# ESP32-P4-LP register map
Vendor: ESPRESSIF SYSTEMS (SHANGHAI) CO., LTD.; Series: ESP32 P-Series; File version: 3
CPU: RV32IMAC r0p0, little endian, no MPU, no FPU, 0 interrupt priority bits
Address unit: 32 bits
Registers are 32-bit, read-write, reset 0x0 unless marked. A register's access mark holds for its fields unless they carry their own. Offsets are from the block's base; [hi:lo] are bit positions; {n}, {i} and the like mark numbered series; 'fields as' and 'values as' point back to an identical list.

## LP_I2C_ANA_MST — LP_I2C_ANA_MST Peripheral
Base 0x50124000
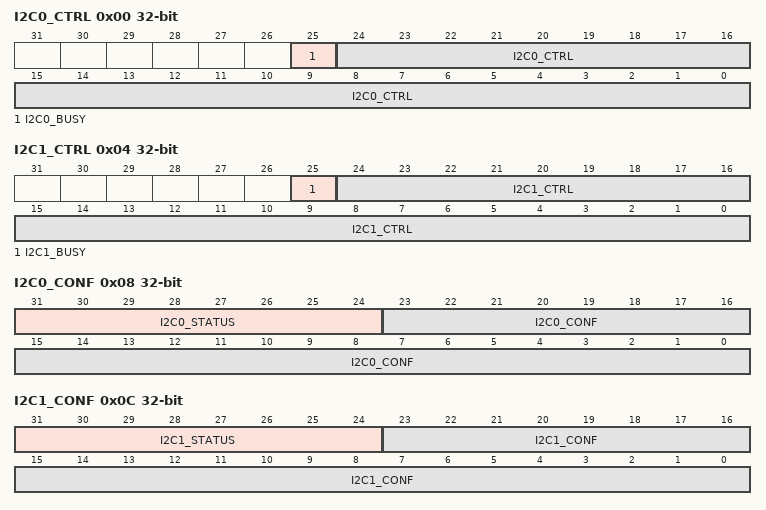
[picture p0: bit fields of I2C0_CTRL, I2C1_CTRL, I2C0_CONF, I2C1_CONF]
0x00 I2C0_CTRL access per field — need des
  [25] I2C0_BUSY ro — need des
  [24:0] I2C0_CTRL rw — need des
0x04 I2C1_CTRL access per field — need des
  [25] I2C1_BUSY ro — need des
  [24:0] I2C1_CTRL rw — need des
0x08 I2C0_CONF access per field — need des
  [31:24] I2C0_STATUS ro — need des
  [23:0] I2C0_CONF rw — need des
0x0C I2C1_CONF access per field — need des
  [31:24] I2C1_STATUS ro — need des
  [23:0] I2C1_CONF rw — need des
0x10 I2C_BURST_CONF — need des
  [31:0] I2C_MST_BURST_CTRL
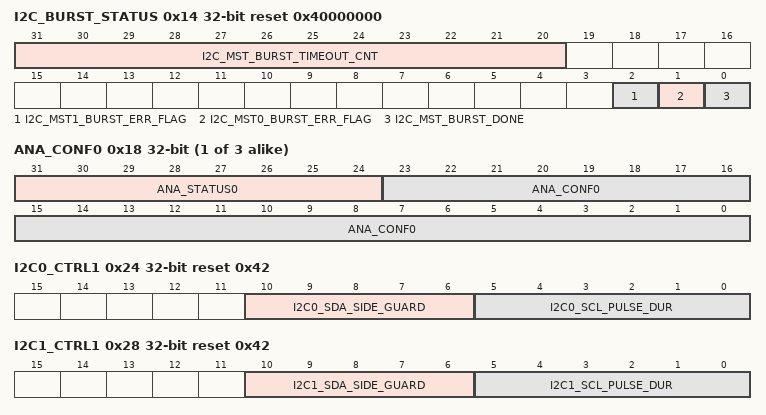
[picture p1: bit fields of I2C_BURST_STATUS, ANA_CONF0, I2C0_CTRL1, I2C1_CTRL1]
0x14 I2C_BURST_STATUS access per field reset 0x40000000 — need des
  [31:20] I2C_MST_BURST_TIMEOUT_CNT rw — need des
  [2] I2C_MST1_BURST_ERR_FLAG ro — need des
  [1] I2C_MST0_BURST_ERR_FLAG ro — need des
  [0] I2C_MST_BURST_DONE ro — need des
{0x18+4i} ANA_CONF{i} access per field (i=0..2) — need des
  [31:24] ANA_STATUS{i} ro — need des
  [23:0] ANA_CONF{i} rw — need des
0x24 I2C0_CTRL1 reset 0x42 — need des
  [10:6] I2C0_SDA_SIDE_GUARD — need des
  [5:0] I2C0_SCL_PULSE_DUR — need des
0x28 I2C1_CTRL1 reset 0x42 — need des
  [10:6] I2C1_SDA_SIDE_GUARD — need des
  [5:0] I2C1_SCL_PULSE_DUR — need des
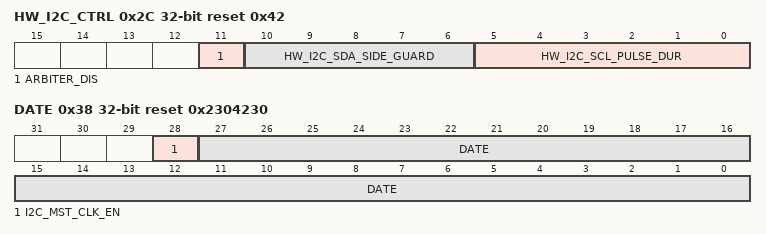
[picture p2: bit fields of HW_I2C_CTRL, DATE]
0x2C HW_I2C_CTRL reset 0x42 — need des
  [11] ARBITER_DIS — need des
  [10:6] HW_I2C_SDA_SIDE_GUARD — need des
  [5:0] HW_I2C_SCL_PULSE_DUR — need des
0x30 NOUSE — need des
  [31:0] I2C_MST_NOUSE
0x34 CLK160M — need des
  [0] CLK_I2C_MST_SEL_160M
0x38 DATE reset 0x2304230 — need des
  [28] I2C_MST_CLK_EN — need des
  [27:0] DATE — need des

## LP_INTR — Low-power Interrupt Controller
Base 0x5012C000
0x00 SW_INT_RAW — need_des
  [31] LP_SW_INT_RAW
0x04 SW_INT_ST ro — need_des
  [31] LP_SW_INT_ST
0x08 SW_INT_ENA — need_des
  [31] LP_SW_INT_ENA
0x0C SW_INT_CLR wo — need_des
  [31] LP_SW_INT_CLR
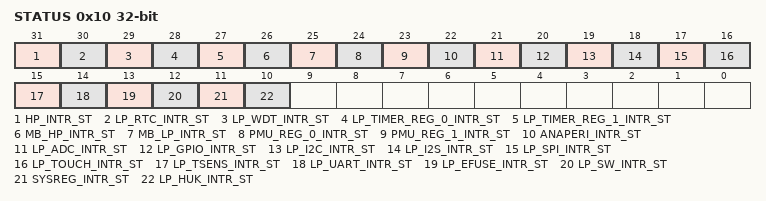
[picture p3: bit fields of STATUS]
0x10 STATUS ro — need_des
  [31] HP_INTR_ST — need_des
  [30] LP_RTC_INTR_ST — need_des
  [29] LP_WDT_INTR_ST — need_des
  [28] LP_TIMER_REG_0_INTR_ST — need_des
  [27] LP_TIMER_REG_1_INTR_ST — need_des
  [26] MB_HP_INTR_ST — need_des
  [25] MB_LP_INTR_ST — need_des
  [24] PMU_REG_0_INTR_ST — need_des
  [23] PMU_REG_1_INTR_ST — need_des
  [22] ANAPERI_INTR_ST — need_des
  [21] LP_ADC_INTR_ST — need_des
  [20] LP_GPIO_INTR_ST — need_des
  [19] LP_I2C_INTR_ST — need_des
  [18] LP_I2S_INTR_ST — need_des
  [17] LP_SPI_INTR_ST — need_des
  [16] LP_TOUCH_INTR_ST — need_des
  [15] LP_TSENS_INTR_ST — need_des
  [14] LP_UART_INTR_ST — need_des
  [13] LP_EFUSE_INTR_ST — need_des
  [12] LP_SW_INTR_ST — need_des
  [11] SYSREG_INTR_ST — need_des
  [10] LP_HUK_INTR_ST — need_des
0x3FC DATE — need_des
  [31] CLK_EN

## LP_IO_MUX — Low-power Input/Output Multiplexer
Base 0x5012B000
0x00 CLK_EN reset 0x1 — Reserved
  [0] REG_CLK_EN
0x04 VER_DATE reset 0x230313 — Reserved
  [27:0] REG_VER_DATE
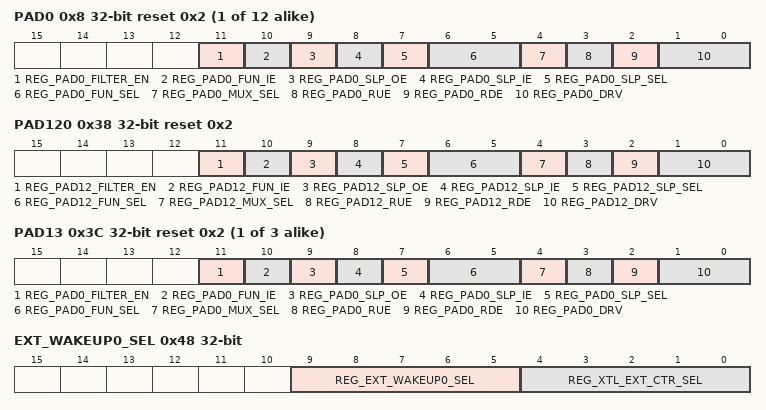
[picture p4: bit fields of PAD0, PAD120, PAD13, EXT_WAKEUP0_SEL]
{0x8+4i} PAD{i} reset 0x2 (i=0..11) — Reserved
  [11] REG_PAD{i}_FILTER_EN — need des
  [10] REG_PAD{i}_FUN_IE — input enable in work mode
  [9] REG_PAD{i}_SLP_OE — output enable in sleep mode
  [8] REG_PAD{i}_SLP_IE — input enable in sleep mode
  [7] REG_PAD{i}_SLP_SEL — 1: enable sleep mode during sleep,0: no sleep mode
  [6:5] REG_PAD{i}_FUN_SEL — function sel
  [4] REG_PAD{i}_MUX_SEL — 1:use LP GPIO,0: use digital GPIO
  [3] REG_PAD{i}_RUE — Reserved
  [2] REG_PAD{i}_RDE — Reserved
  [1:0] REG_PAD{i}_DRV — Reserved
0x38 PAD120 reset 0x2 — Reserved
  [11] REG_PAD12_FILTER_EN — need des
  [10] REG_PAD12_FUN_IE — input enable in work mode
  [9] REG_PAD12_SLP_OE — output enable in sleep mode
  [8] REG_PAD12_SLP_IE — input enable in sleep mode
  [7] REG_PAD12_SLP_SEL — 1: enable sleep mode during sleep,0: no sleep mode
  [6:5] REG_PAD12_FUN_SEL — function sel
  [4] REG_PAD12_MUX_SEL — 1:use LP GPIO,0: use digital GPIO
  [3] REG_PAD12_RUE — Reserved
  [2] REG_PAD12_RDE — Reserved
  [1:0] REG_PAD12_DRV — Reserved
{0x8+4i} PAD{i} reset 0x2 (i=13..15) — Reserved
  fields as PAD0
0x48 EXT_WAKEUP0_SEL — Reserved
  [9:5] REG_EXT_WAKEUP0_SEL — Reserved
  [4:0] REG_XTL_EXT_CTR_SEL — select LP GPIO 0 ~ 15 to control XTAL
0x4C LP_PAD_HOLD — Reserved
  [15:0] REG_LP_GPIO_HOLD
0x50 LP_PAD_HYS — Reserved
  [15:0] REG_LP_GPIO_HYS
